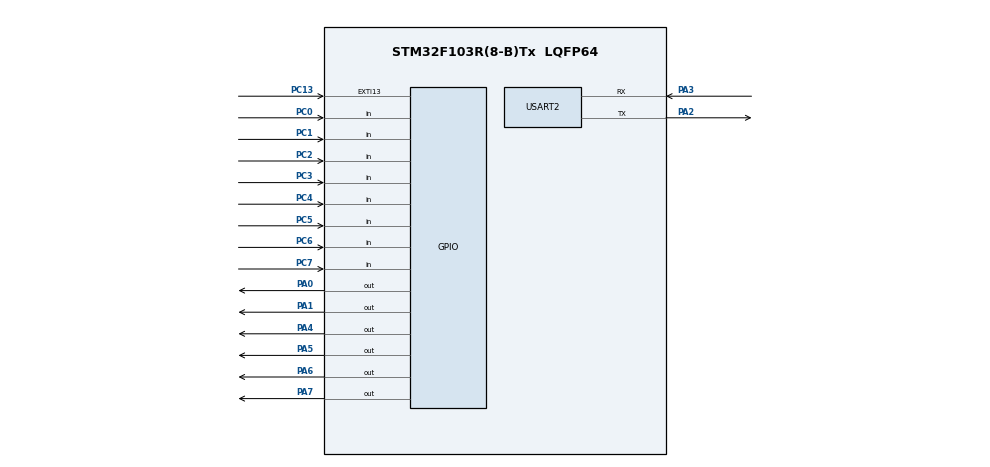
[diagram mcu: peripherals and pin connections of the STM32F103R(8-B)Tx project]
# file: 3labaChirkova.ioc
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FREERTOS.Queues01=myQueue01,4,uint32_t,0,Dynamic,NULL,NULL
FREERTOS.Tasks01=defaultTask,0,128,StartDefaultTask,Default,NULL,Dynamic,NULL,NULL;myTaskReceive,0,128,StartTaskReceive,Default,NULL,Dynamic,NULL,NULL
Mcu.Family=STM32F1
Mcu.Name=STM32F103R(8-B)Tx
Mcu.Package=LQFP64
NVIC.EXTI15_10_IRQn=true\:5\:0\:false\:false\:true\:true\:true\:true
NVIC.PriorityGroup=NVIC_PRIORITYGROUP_4
NVIC.TIM1_UP_IRQn=true\:5\:0\:false\:false\:true\:true\:true\:true
PA0-WKUP.Signal=GPIO_Output
PA1.Signal=GPIO_Output
PA13.Mode=Serial_Wire
PA13.Signal=SYS_JTMS-SWDIO
PA14.Mode=Serial_Wire
PA14.Signal=SYS_JTCK-SWCLK
PA2.Mode=Asynchronous
PA2.Signal=USART2_TX
PA3.Mode=Asynchronous
PA3.Signal=USART2_RX
PA4.GPIO_PuPd=GPIO_PULLDOWN
PA4.Signal=GPIO_Output
PA5.Signal=GPIO_Output
PA6.Signal=GPIO_Output
PA7.Signal=GPIO_Output
PC0.Signal=GPIO_Input
PC1.Signal=GPIO_Input
PC13-TAMPER-RTC.Signal=GPXTI13
PC2.Signal=GPIO_Input
PC3.Signal=GPIO_Input
PC4.Signal=GPIO_Input
PC5.Signal=GPIO_Input
PC6.Signal=GPIO_Input
PC7.Signal=GPIO_Input
ProjectManager.HeapSize=0x200
ProjectManager.StackSize=0x400
ProjectManager.TargetToolchain=STM32CubeIDE
RCC.APB1Freq_Value=8000000
RCC.APB2Freq_Value=8000000
TIM1.Period=1999
TIM1.Prescaler=4999
USART2.VirtualMode=VM_ASYNC
VP_FREERTOS_VS_CMSIS_V1.Mode=CMSIS_V1
VP_TIM1_VS_ClockSourceINT.Mode=Internal
board=custom

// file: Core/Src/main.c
/* USER CODE BEGIN Header */
/**
  ******************************************************************************
  * @file           : main.c
  * @brief          : Main program body
  ******************************************************************************
  * @attention
  *
  * Copyright (c) 2021 STMicroelectronics.
  * All rights reserved.
  *
  * This software is licensed under terms that can be found in the LICENSE file
  * in the root directory of this software component.
  * If no LICENSE file comes with this software, it is provided AS-IS.
  *
  ******************************************************************************
  */
/* USER CODE END Header */
#include "main.h"
#include "cmsis_os.h"

/* USER CODE BEGIN Includes */
#include "freertos_task.h"
/* USER CODE END Includes */

TIM_HandleTypeDef htim1;

UART_HandleTypeDef huart2;

osThreadId defaultTaskHandle;
osThreadId myTaskReceiveHandle;
osMessageQId myQueue01Handle;

void SystemClock_Config(void);
static void MX_GPIO_Init(void);
static void MX_TIM1_Init(void);
static void MX_USART2_UART_Init(void);
void StartDefaultTask(void const * argument);
void StartTaskReceive(void const * argument);

int main(void)
{
  /* USER CODE BEGIN 1 */
	QueueHandle_t xUartQueue = NULL;
  /* USER CODE END 1 */

  /* MCU Configuration--------------------------------------------------------*/

  /* Reset of all peripherals, Initializes the Flash interface and the Systick. */
  HAL_Init();

  /* Configure the system clock */
  SystemClock_Config();

  /* Initialize all configured peripherals */
  MX_GPIO_Init();
  MX_TIM1_Init();
  MX_USART2_UART_Init();

  /* Create the queue(s) */
  /* definition and creation of myQueue01 */
  osMessageQDef(myQueue01, 4, uint32_t);
  myQueue01Handle = osMessageCreate(osMessageQ(myQueue01), NULL);

  /* USER CODE BEGIN RTOS_QUEUES */
  /* add queues, ... */
  xUartQueue = xQueueCreate( 10, sizeof( char* ) ); //Создайте очередь, способную содержать 10 длинных значений без знака.

  /* USER CODE END RTOS_QUEUES */

  /* Create the thread(s) */
  /* definition and creation of defaultTask */
  osThreadDef(defaultTask, StartDefaultTask, osPriorityNormal, 0, 128);
  defaultTaskHandle = osThreadCreate(osThread(defaultTask), xUartQueue);

  /* definition and creation of myTaskReceive */
  osThreadDef(myTaskReceive, StartTaskReceive, osPriorityNormal, 0, 128);
  myTaskReceiveHandle = osThreadCreate(osThread(myTaskReceive), xUartQueue);

  /* USER CODE BEGIN RTOS_THREADS */
  /* add threads, ... */
  var10_task_create(xUartQueue);
  /* USER CODE END RTOS_THREADS */

  /* Start scheduler */
  osKernelStart();

  /* We should never get here as control is now taken by the scheduler */
  /* Infinite loop */
  /* USER CODE BEGIN WHILE */
  while (1)
  {
//      if(ex.pin_c == 1)                                 //если ex.pin_c = 1 то прерывание произошло и выполняется тело цикла
//          {     ex.pin_c = 0;                           //устанавливаем ex.pin_c = 0, чтоб тело цикла if(ex.pin_c == 1) не выполнялось при повторном прохождении программы
//                tim.i = 0;                              //устанавливаем tim.i = 0, чтоб тело цикла if(tim.i==ex.i) (39 строка) выполнялась до того момента пока ex.i = 0
//              ex.i = 0;                               //устанавливаем tim.i = 0, обновление счетчика while(ex.i<ex.a*2) вкл и выкл светодиода
//                ex.x = GPIOC->IDR & (GPIO_PIN_0|GPIO_PIN_1|GPIO_PIN_2|GPIO_PIN_3|GPIO_PIN_4|GPIO_PIN_5|GPIO_PIN_6|GPIO_PIN_7) ; // считываем значиние с порта С (0-7 пинов)                               //устанавливаем i = 0
//            if (ex.x== pin)                             //если введенное число равно секретному коду, тело цикла выполняется
//                {
//                    ex.a = 1;                           //значения "ex.a" определяется сколько раз должен загореться светодтод
//                    TIM1->ARR = tim.count2;             //установка таймера на count2=10000-1
//                                            }
//            else
//                {   ex.a = 3;                           //устанавливаем ex.a = 3
//                    TIM1->ARR = tim.count1;             //установка таймера на count1=2000-1
//                                           }
//            TIM1->CNT=0;                                // сбрасываем значение таймера
//        }
//      if(tim.i==ex.i)                                     //условие при котором будет выполняться тело цикла if, т.к. до прерывания у нас tim.i = 1 а ex.i = 0 то тело цикла не будет выполнятся т.е. светодиоды не переключаются
//          {
//              while(ex.i<ex.a*2)                          //пока ex.i меньше ex.a*2 цикл выполняется
//                  {
//                    HAL_GPIO_TogglePin(GPIOA, GPIO_PIN_0|GPIO_PIN_1|GPIO_PIN_2|GPIO_PIN_3
//                          |GPIO_PIN_4|GPIO_PIN_5|GPIO_PIN_6|GPIO_PIN_7 );                  //установка 1 на пины от 0 до 7 (11111111 = 0xff)
//                    HAL_TIM_Base_Start_IT(&htim1);  			 //включаем таймер
//                    ex.i++;                    			 // ex.i = ex.i + 1
//                    break;                     			 //выход из цикла
//                  }
//           }

    /* USER CODE END WHILE */

  }
}

void SystemClock_Config(void)
{
  RCC_OscInitTypeDef RCC_OscInitStruct = {0};
  RCC_ClkInitTypeDef RCC_ClkInitStruct = {0};

  /** Initializes the RCC Oscillators according to the specified parameters
  * in the RCC_OscInitTypeDef structure.
  */
  RCC_OscInitStruct.OscillatorType = RCC_OSCILLATORTYPE_HSI;
  RCC_OscInitStruct.HSIState = RCC_HSI_ON;
  RCC_OscInitStruct.HSICalibrationValue = RCC_HSICALIBRATION_DEFAULT;
  RCC_OscInitStruct.PLL.PLLState = RCC_PLL_NONE;
  if (HAL_RCC_OscConfig(&RCC_OscInitStruct) != HAL_OK)
  {
    Error_Handler();
  }
  /** Initializes the CPU, AHB and APB buses clocks
  */
  RCC_ClkInitStruct.ClockType = RCC_CLOCKTYPE_HCLK|RCC_CLOCKTYPE_SYSCLK
                              |RCC_CLOCKTYPE_PCLK1|RCC_CLOCKTYPE_PCLK2;
  RCC_ClkInitStruct.SYSCLKSource = RCC_SYSCLKSOURCE_HSI;
  RCC_ClkInitStruct.AHBCLKDivider = RCC_SYSCLK_DIV1;
  RCC_ClkInitStruct.APB1CLKDivider = RCC_HCLK_DIV1;
  RCC_ClkInitStruct.APB2CLKDivider = RCC_HCLK_DIV1;

  if (HAL_RCC_ClockConfig(&RCC_ClkInitStruct, FLASH_LATENCY_0) != HAL_OK)
  {
    Error_Handler();
  }
}

static void MX_TIM1_Init(void)
{

  TIM_ClockConfigTypeDef sClockSourceConfig = {0};
  TIM_MasterConfigTypeDef sMasterConfig = {0};

  htim1.Instance = TIM1;
  htim1.Init.Prescaler = 4999;
  htim1.Init.CounterMode = TIM_COUNTERMODE_UP;
  htim1.Init.Period = 1999;
  htim1.Init.ClockDivision = TIM_CLOCKDIVISION_DIV1;
  htim1.Init.RepetitionCounter = 0;
  htim1.Init.AutoReloadPreload = TIM_AUTORELOAD_PRELOAD_DISABLE;
  if (HAL_TIM_Base_Init(&htim1) != HAL_OK)
  {
    Error_Handler();
  }
  sClockSourceConfig.ClockSource = TIM_CLOCKSOURCE_INTERNAL;
  if (HAL_TIM_ConfigClockSource(&htim1, &sClockSourceConfig) != HAL_OK)
  {
    Error_Handler();
  }
  sMasterConfig.MasterOutputTrigger = TIM_TRGO_RESET;
  sMasterConfig.MasterSlaveMode = TIM_MASTERSLAVEMODE_DISABLE;
  if (HAL_TIMEx_MasterConfigSynchronization(&htim1, &sMasterConfig) != HAL_OK)
  {
    Error_Handler();
  }

}

static void MX_USART2_UART_Init(void)
{

  huart2.Instance = USART2;
  huart2.Init.BaudRate = 115200;
  huart2.Init.WordLength = UART_WORDLENGTH_8B;
  huart2.Init.StopBits = UART_STOPBITS_1;
  huart2.Init.Parity = UART_PARITY_NONE;
  huart2.Init.Mode = UART_MODE_TX_RX;
  huart2.Init.HwFlowCtl = UART_HWCONTROL_NONE;
  huart2.Init.OverSampling = UART_OVERSAMPLING_16;
  if (HAL_UART_Init(&huart2) != HAL_OK)
  {
    Error_Handler();
  }

}

static void MX_GPIO_Init(void)
{
  GPIO_InitTypeDef GPIO_InitStruct = {0};

  /* GPIO Ports Clock Enable */
  __HAL_RCC_GPIOC_CLK_ENABLE();
  __HAL_RCC_GPIOA_CLK_ENABLE();

  /*Configure GPIO pin Output Level */
  HAL_GPIO_WritePin(GPIOA, GPIO_PIN_0|GPIO_PIN_1|GPIO_PIN_4|GPIO_PIN_5
                          |GPIO_PIN_6|GPIO_PIN_7, GPIO_PIN_RESET);

  /*Configure GPIO pin : PC13 */
  GPIO_InitStruct.Pin = GPIO_PIN_13;
  GPIO_InitStruct.Mode = GPIO_MODE_IT_RISING;
  GPIO_InitStruct.Pull = GPIO_NOPULL;
  HAL_GPIO_Init(GPIOC, &GPIO_InitStruct);

  /*Configure GPIO pins : PC0 PC1 PC2 PC3
                           PC4 PC5 PC6 PC7 */
  GPIO_InitStruct.Pin = GPIO_PIN_0|GPIO_PIN_1|GPIO_PIN_2|GPIO_PIN_3
                          |GPIO_PIN_4|GPIO_PIN_5|GPIO_PIN_6|GPIO_PIN_7;
  GPIO_InitStruct.Mode = GPIO_MODE_INPUT;
  GPIO_InitStruct.Pull = GPIO_NOPULL;
  HAL_GPIO_Init(GPIOC, &GPIO_InitStruct);

  /*Configure GPIO pins : PA0 PA1 PA5 PA6
                           PA7 */
  GPIO_InitStruct.Pin = GPIO_PIN_0|GPIO_PIN_1|GPIO_PIN_5|GPIO_PIN_6
                          |GPIO_PIN_7;
  GPIO_InitStruct.Mode = GPIO_MODE_OUTPUT_PP;
  GPIO_InitStruct.Pull = GPIO_NOPULL;
  GPIO_InitStruct.Speed = GPIO_SPEED_FREQ_LOW;
  HAL_GPIO_Init(GPIOA, &GPIO_InitStruct);

  /*Configure GPIO pin : PA4 */
  GPIO_InitStruct.Pin = GPIO_PIN_4;
  GPIO_InitStruct.Mode = GPIO_MODE_OUTPUT_PP;
  GPIO_InitStruct.Pull = GPIO_PULLDOWN;
  GPIO_InitStruct.Speed = GPIO_SPEED_FREQ_LOW;
  HAL_GPIO_Init(GPIOA, &GPIO_InitStruct);

  /* EXTI interrupt init*/
  HAL_NVIC_SetPriority(EXTI15_10_IRQn, 5, 0);
  HAL_NVIC_EnableIRQ(EXTI15_10_IRQn);

}

void StartDefaultTask(void const * argument)
{
  for(;;)
  {
    osDelay(1);
  }
}

void StartTaskReceive(void const * argument)
{

  for(;;)
  {
    osDelay(1);
  }
}

void Error_Handler(void)
{
  __disable_irq();
  while (1)
  {
  }
}
